# max32665 register map
Vendor: Maxim-Integrated; Series: ARMCM3; File version: 1.0
CPU: CM4 r2p1, little endian, MPU, FPU, 3 interrupt priority bits
Registers are 32-bit, read-write, reset 0x0 unless marked. A register's access mark holds for its fields unless they carry their own. Offsets are from the block's base; [hi:lo] are bit positions; {n}, {i} and the like mark numbered series; 'fields as' and 'values as' point back to an identical list.

## SPI17Y — SPI peripheral.
Base 0x400BE000
Same registers: SPI17Y1 0x40046000, SPI17Y2 0x40047000
0x00 DATA32 — Register for reading and writing the FIFO.
  [31:0] DATA — Read to pull from RX FIFO, write to put into TX FIFO.
{0x0+2i} DATA16[{i}] (i=0..1) 16-bit (alternate view of DATA32) — Register for reading and writing the FIFO.
  [15:0] DATA — Read to pull from RX FIFO, write to put into TX FIFO.
{0x0+i} DATA8[{i}] (i=0..3) 8-bit (alternate view of DATA32) — Register for reading and writing the FIFO.
  [7:0] DATA — Read to pull from RX FIFO, write to put into TX FIFO.
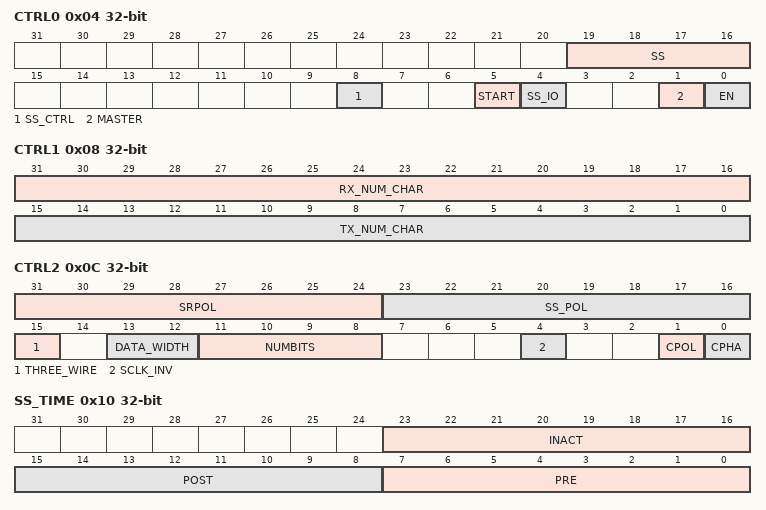
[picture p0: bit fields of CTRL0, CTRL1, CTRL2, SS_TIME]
0x04 CTRL0 — Register for controlling SPI peripheral.
  [19:16] SS — Slave Select, when in Master mode selects which Slave devices are selected. More than one Slave device can be selected.
    1=SS0 is selected; 2=SS1 is selected; 4=SS2 is selected; 8=SS3 is selected
  [8] SS_CTRL — Start Select Control. Used in Master mode to control the behavior of the Slave Select signal at the end of a transaction.
    0=DEASSERT (SPI De-asserts Slave Select at the end of a transaction.); 1=ASSERT (SPI leaves Slave Select asserted at the end of a transaction.)
  [5] START — Start Transmit.
    1=start (Master Initiates a transaction, this bit is self clearing when transactions are done. If a transaction cimpletes, and the TX FIFO is empty, the Master halts, if a transaction completes, and the TX FIFO is not empty, the Master initiates another transaction.)
  [4] SS_IO — Slave Select 0, IO direction, to support Multi-Master mode,Slave Select 0 can be input in Master mode. This bit has no effect in slave mode.
    0=output (Slave select 0 is output.); 1=input (Slave Select 0 is input, only valid if MMEN=1.)
  [1] MASTER — Master Mode Enable.
    0=dis (SPI is Slave mode.); 1=en (SPI is Master mode.)
  [0] EN — SPI Enable.
    0=dis (SPI is disabled.); 1=en (SPI is enabled.)
0x08 CTRL1 — Register for controlling SPI peripheral.
  [31:16] RX_NUM_CHAR — Nubmer of Characters to receive.
  [15:0] TX_NUM_CHAR — Nubmer of Characters to transmit.
0x0C CTRL2 — Register for controlling SPI peripheral.
  [31:24] SRPOL — Slave Ready Polarity, each Slave Ready can have unique polarity.
    1=SR0_high (SR0 active high.); 2=SR1_high (SR1 active high.); 4=SR2_high (SR2 active high.); 8=SR3_high (SR3 active high.); 16=SR4_high (SR4 active high.); 32=SR5_high (SR5 active high.); 64=SR6_high (SR6 active high.); 128=SR7_high (SR7 active high.)
  [23:16] SS_POL — Slave Select Polarity, each Slave Select can have unique polarity.
    1=SS0_high (SS0 active high.); 2=SS1_high (SS1 active high.); 4=SS2_high (SS2 active high.); 8=SS3_high (SS3 active high.)
  [15] THREE_WIRE — Three Wire mode. MOSI/MISO pin(s) shared. Only Mono mode suports Four-Wire.
    0=dis (Use four wire mode (Mono only).); 1=en (Use three wire mode.)
  [13:12] DATA_WIDTH — SPI Data width.
    0=Mono (1 data pin.); 1=Dual (2 data pins.); 2=Quad (4 data pins.)
  [11:8] NUMBITS — Number of Bits per character.
    0=16 bits per character
  [4] SCLK_INV — Reserved - Must Always Be Cleared to 0.
  [1] CPOL — Clock Polarity.
    0=Normal Clock. Use when in SPI Mode 0 and Mode 1; 1=Inverted Clock. Use when in SPI Mode 2 and Mode 3
  [0] CPHA — Clock Phase.
    0=Rising_Edge (Data Sampled on clock rising edge. Use when in SPI Mode 0 and Mode 2); 1=Falling_Edge (Data Sampled on clock falling edge. Use when in SPI Mode 1 and Mode 3)
0x10 SS_TIME — Register for controlling SPI peripheral/Slave Select Timing.
  [23:16] INACT — Slave Select Inactive delay.
    0=256 system clocks between transactions
  [15:8] POST — Slave Select Post delay 2.
    0=256 system clocks between last serial clock edge and SS inactive
  [7:0] PRE — Slave Select Pre delay 1.
    0=256 system clocks between SS active and first serial clock edge
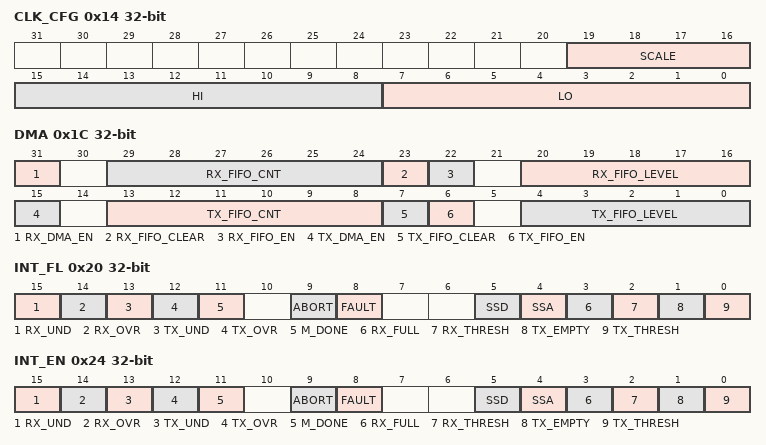
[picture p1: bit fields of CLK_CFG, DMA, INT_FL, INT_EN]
0x14 CLK_CFG — Register for controlling SPI clock rate.
  [19:16] SCALE — System Clock scale factor. Scales the AMBA clock by 2^SCALE before generating serial clock.
  [15:8] HI — High duty cycle control. In timer mode, reload[15:8].
    0=Dis (Duty cycle control of serial clock generation is disabled.)
  [7:0] LO — Low duty cycle control. In timer mode, reload[7:0].
    values as HI
0x1C DMA — Register for controlling DMA.
  [31] RX_DMA_EN — RX DMA Enable.
    0=dis (RX DMA requests are disabled, any pending DMA requests are cleared.); 1=en (RX DMA requests are enabled.)
  [29:24] RX_FIFO_CNT ro — Count of entries in RX FIFO.
  [23] RX_FIFO_CLEAR — Clear RX FIFO, clear is accomplished by resetting the read and write pointers. This should be done when FIFO is not being accessed on the SPI side.
    1=CLEAR (Clear the Receive FIFO, clears any pending RX FIFO status.)
  [22] RX_FIFO_EN — Receive FIFO enabled for SPI transactions.
    0=DIS (Receive FIFO is not enabled.); 1=en (Receive FIFO is enabled.)
  [20:16] RX_FIFO_LEVEL — Receive FIFO level that will trigger a DMA request, also level for threshold status. When RX FIFO has more than this many bytes, the associated events and conditions are triggered.
  [15] TX_DMA_EN — TX DMA Enable.
    0=DIS (TX DMA requests are disabled, andy pending DMA requests are cleared.); 1=en (TX DMA requests are enabled.)
  [13:8] TX_FIFO_CNT ro — Count of entries in TX FIFO.
  [7] TX_FIFO_CLEAR — Clear TX FIFO, clear is accomplished by resetting the read and write pointers. This should be done when FIFO is not being accessed on the SPI side. .
    1=CLEAR (Clear the Transmit FIFO, clears any pending TX FIFO status.)
  [6] TX_FIFO_EN — Transmit FIFO enabled for SPI transactions.
    0=dis (Transmit FIFO is not enabled.); 1=en (Transmit FIFO is enabled.)
  [4:0] TX_FIFO_LEVEL — Transmit FIFO level that will trigger a DMA request, also level for threshold status. When TX FIFO has fewer than this many bytes, the associated events and conditions are triggered.
0x20 INT_FL — Register for reading and clearing interrupt flags. All bits are write 1 to clear.
  [all] fields
    1=clear (Flag is set when value read is 1. Write 1 to clear this flag.)
  [15] RX_UND — Receive FIFO Underrun, set when the AMBA side attempts to read data from an empty receive FIFO.
  [14] RX_OVR — Receive FIFO Overrun, set when the SPI side attempts to write to a full receive FIFO.
  [13] TX_UND — Transmit FIFO Underrun, set when the SPI side attempts to read data from an empty transmit FIFO.
  [12] TX_OVR — Transmit FIFO Overrun, set when the AMBA side attempts to write data to a full transmit FIFO.
  [11] M_DONE — Master Done, set when SPI Master has completed any transactions.
  [9] ABORT — Slave Abort Detected.
  [8] FAULT — Multi-Master Mode Fault.
  [5] SSD — Slave Select Deasserted.
  [4] SSA — Slave Select Asserted.
  [3] RX_FULL — RX FIFO FULL.
  [2] RX_THRESH — RX FIFO Threshold Crossed.
  [1] TX_EMPTY — TX FIFO Empty.
  [0] TX_THRESH — TX FIFO Threshold Crossed.
0x24 INT_EN — Register for enabling interrupts.
  [all] fields
    0=dis (Interrupt is disabled.); 1=en (Interrupt is enabled.)
  [15] RX_UND — Receive FIFO Underrun interrupt enable.
  [14] RX_OVR — Receive FIFO Overrun interrupt enable.
  [13] TX_UND — Transmit FIFO Underrun interrupt enable.
  [12] TX_OVR — Transmit FIFO Overrun interrupt enable.
  [11] M_DONE — Master Done interrupt enable.
  [9] ABORT — Slave Abort Detected interrupt enable.
  [8] FAULT — Multi-Master Mode Fault interrupt enable.
  [5] SSD — Slave Select Deasserted interrupt enable.
  [4] SSA — Slave Select Asserted interrupt enable.
  [3] RX_FULL — RX FIFO FULL interrupt enable.
  [2] RX_THRESH — RX FIFO Threshold Crossed interrupt enable.
  [1] TX_EMPTY — TX FIFO Empty interrupt enable.
  [0] TX_THRESH — TX FIFO Threshold interrupt enable.
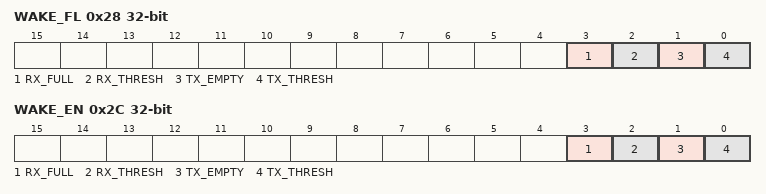
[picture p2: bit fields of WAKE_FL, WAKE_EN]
0x28 WAKE_FL — Register for wake up flags. All bits in this register are write 1 to clear.
  [all] fields
    values as the fields of INT_FL
  [3] RX_FULL — Wake on RX FIFO Full.
  [2] RX_THRESH — Wake on RX FIFO Threshold Crossed.
  [1] TX_EMPTY — Wake on TX FIFO Empty.
  [0] TX_THRESH — Wake on TX FIFO Threshold Crossed.
0x2C WAKE_EN — Register for wake up enable.
  [all] fields
    0=dis (Wakeup source disabled.); 1=en (Wakeup source enabled.)
  [3] RX_FULL — Wake on RX FIFO Full Enable.
  [2] RX_THRESH — Wake on RX FIFO Threshold Crossed Enable.
  [1] TX_EMPTY — Wake on TX FIFO Empty Enable.
  [0] TX_THRESH — Wake on TX FIFO Threshold Crossed Enable.
0x30 STAT ro — SPI Status register.
  [0] BUSY — SPI active status. In Master mode, set when transaction starts, cleared when last bit of last character is acted upon and Slave Select de-assertion would occur. In Slave mode, set when Slave Select is asserted, cleared when Slave Select is de-asserted. Not used in Timer mode.
    0=not (SPI not active.); 1=active (SPI active.)
